# PRU_ICSS_MII_RT register map
Vendor: Texas Instruments
Peripheral module from a debugger description file (folder am437x).
Registers are 32-bit, read-only, no defined reset value unless marked. A register's access mark holds for its fields unless they carry their own. Offsets are as the file gives them; lines under a group give offsets from that group; [hi:lo] are bit positions; {n}, {i} and the like mark numbered series; 'fields as' and 'values as' point back to an identical list; <NAME> marks a mode.

## PRU_ICSS_MII_RT
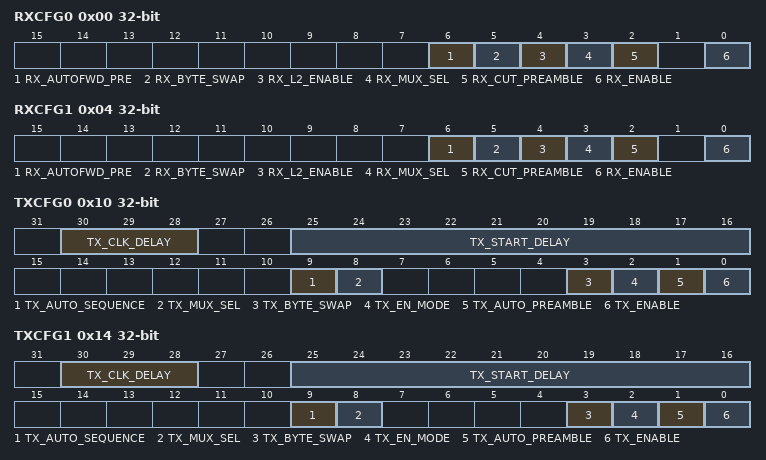
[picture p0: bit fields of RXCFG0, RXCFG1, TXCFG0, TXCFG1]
0x00 RXCFG0 access per field — RX CONFIG0
  [6] RX_AUTOFWD_PRE rw — Enables auto-forward of received preamble. When enabled, this will forward the preamble nibbles including the SFD to the TX L1 FIFO that is attached to the PRU. First data byte seen by PRU R31 and/or RX L2 is destination address (DA). Odd number of preamble nibbles is supported in this mode. For example, 0x55D. Note that new RX should only occur after the current TX completes. 0x0: Disable 0x1: Enable, it must disable RX_CUT_PREAMBLE and TX_AUTO_PREAMBLE
  [5] RX_BYTE_SWAP rw — Defines the order of Byte0/1 placement for RX R31 and RX L2. Note that if TX_AUTO_SEQUENCE enabled, this bit cannot get enable since TX_BYTE_SWAP on swaps the PRU output. This bit must be selected/updated when the port is disabled or there is no traffic. 0x0: R31[15:8]/RXL2[15:8] = Byte1{Nibble3,Nibble2} R31[ 7:0]/RXL2[7:0] = Byte0{Nibble1,Nibble0} 0x1: R31[15:8]/RXL2[15:8] = Byte0{Nibble1,Nibble0} R31[ 7:0]/RXL2[7:0] = Byte1{Nibble3,Nibble2} Nibble0 is the first nibble received.
  [4] RX_L2_ENABLE rw — Enables RX L2 buffer. 0x0: Disable (RX L2 can function as generic scratch pad) 0x1: Enable
  [3] RX_MUX_SEL rw — Selects receive data source. Typically, the setting for this will not be identical for the two MII receive configuration registers. 0x0: MII RX Data from Port 0 (default for RXCFG0) 0x1: MII RX Data from Port 1 (default for RXCFG1)
  [2] RX_CUT_PREAMBLE rw — Removes received preamble. 0x0: All data from Ethernet PHY are passed on to PRU register. This assumes Ethernet PHY which does not shorten the preamble. 0x1: MII interface suppresses preamble and sync frame delimiter. First data byte seen by PRU register is destination address.
  [0] RX_ENABLE rw — Enables the receive traffic currently selected by RX_MUX_SELECT. 0x0: Disable 0x1: Enable
0x04 RXCFG1 access per field — RX CONFIG1
  fields as RXCFG0
0x10 TXCFG0 access per field — TX CONFIG0
  [30:28] TX_CLK_DELAY rw — In order to guarantee the MII_RT IO timing values published in the device data manual, the ocp_clk must be configured for 200MHz and TX_CLK_DELAY must be set to 6h.
  [25:16] TX_START_DELAY rw — Defines the minimum time interval (delay) between receiving the RXDV for the current frame and the start of the transmit interface sending data to the MII interface. Delay value is in units of MII_RT clock cycles, which uses the ocp_clk (default is 200MHz, or 5ns). Default TX_START_DELAY value is 320ns, which is optimized for minimum latency at 16 bit processing. Counter is started with RX_DV signal going active. Transmit interface stops sending data when no more data is written into transmit interface by PRU along with TX_EOF marker bit set. If the TX FIFO has data when the delay expires, then TX will start sending data. But if the TX FIFO is empty, it will not start until the TX FIFO is not empty. It is possible to overflow the TX FIFO with the max delay setting when auto-forwarding is enabled since the time delay is larger than the amount of data it needs to store. As long as TX L1 FIFO overflows, software will need to issue a TX_RESET to reset the TX FIFO. The total delay is 64-byte times (size of TX FIFO), but you need to allow delays for synchronization. Do to this fact, the maximum delay should be 80ns less when auto forwarding is enabled. Therefore, 0x3F0 is the maximum in this configuration.
  [9] TX_AUTO_SEQUENCE rw — Enables transmit auto-sequence. Note the transmit data source is determined by TX_MUX_SEL setting. 0x0: Disable 0x1: Enable, transmit state machine based on events on receiver path that is connected to the respective transmitter. Also, the masking logic is disabled and only the MII data is used.
  [8] TX_MUX_SEL rw — Selects transmit data source. The default/reset setting for TX Port 0 is 1. This setting permits MII TX Port 0 to receive data from PRU1 and the MII TX Port 1 which is connected to PRU0 by default. 0x0: Data from PRU0 (default for TXCFG1) 0x1: Data from PRU1 (default for TXCFG0)
  [3] TX_BYTE_SWAP rw — Defines the order of Byte0/1 placement for TX R30. This bit must be selected/updated when the port is disabled or there is no traffic. 0x0: R30[15:8] = Byte1{Nibble3,Nibble2} R30[ 7:0] = Byte0{Nibble1,Nibble0} R30[31:24] = TX_MASK[15:8] R30[23:16] = TX_MASK[7:0] 0x1: R30[15:8] = Byte0{Nibble1,Nibble0} R30[ 7:0] = Byte1{Nibble3,Nibble2} R30[31:24] = TX_MASK[7:0] R30[23:16] = TX_MASK[15:8] Nibble0 is the first nibble received.
  [2] TX_EN_MODE rw — Enables transmit self clear on TX_EOF event. Note that iep.cmp[3] must be set before transmission will start for TX0, and iep_cmp[4] for TX1. This is a new dependency, in addition to TX L1 FIFO not empty and TX_START_DELAY expiration, to start transmission. 0x0: Disable 0x1: Enable, TX_ENABLE will be clear for a TX_EOF event by itself.
  [1] TX_AUTO_PREAMBLE rw — Transmit data auto-preamble. 0x0: PRU will provide full preamble 0x1: TX FIFO will insert pre-amble automatically. Note that the TX FIFO does not get preloaded with the preamble until the first write occurs. This can cause the latency to be larger than the minimum latency.
  [0] TX_ENABLE rw — Enables transmit traffic on TX PORT. If TX_EN_MODE is set, then TX_ENABLE will self clear during a TX_EOF event. Note Software can use this to pre-fill the TX FIFO and then start the TX frame during non-ECS operations. 0x0: TX PORT is disabled/stopped immediately 0x1: TX PORT is enabled and the frame will start once the IPG counter expired and TX Start Delay counter has expired
0x14 TXCFG1 access per field — TX CONFIG1
  fields as TXCFG0
0x20 TXCRC0 — TX CYCLIC REDUNDANCY CHECK0
  [31:0] TX_CRC32 — FCS (CRC32) data can be read by PRU for diagnostics. It is only valid after 6 clocks after a TX_CRC_HIGH command is given.
0x24 TXCRC1 — TX CYCLIC REDUNDANCY CHECK1
  fields as TXCRC0
0x30 TXIPG0 access per field — TX INTERPACKET GAP0
  [9:0] TX_IPG rw — Defines the minimum of transmit Inter Packet Gap (IPG) which is the number of ocp_clk cycles between the de-assertion of TX_EN and the assertion of TX_EN. The start of the TX will get delayed when the incoming packet IPG is less than defined minimum value. In general, software should program in increments of 8, 40ns to insure the extra delays takes effect.
0x34 TXIPG1 access per field — TX INTERPACKET GAP1
  fields as TXIPG0
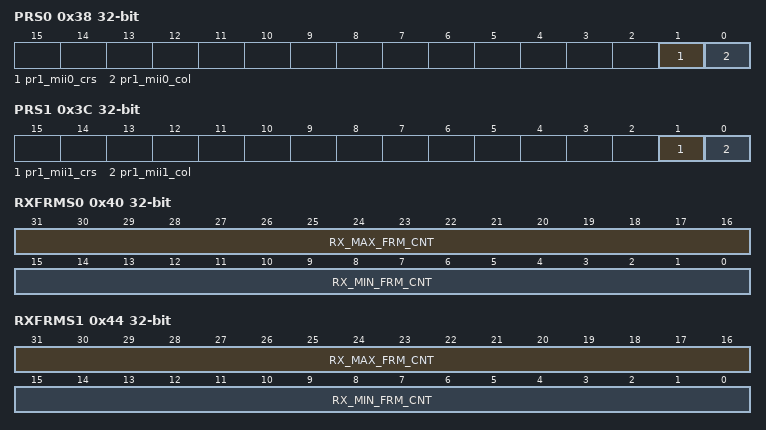
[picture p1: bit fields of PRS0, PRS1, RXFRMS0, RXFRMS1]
0x38 PRS0 — PORT RAW STATUS0
  [1] pr1_mii0_crs — Current state of pr#lt#k#gt#_mii0_crs
  [0] pr1_mii0_col — Current state of pr#lt#k#gt#_mii0_col
0x3C PRS1 — PORT RAW STATUS1
  [1] pr1_mii1_crs — Current state of pr#lt#k#gt#_mii1_crs
  [0] pr1_mii1_col — Current state of pr#lt#k#gt#_mii1_col
0x40 RXFRMS0 rw — RX FRAME SIZE0
  [31:16] RX_MAX_FRM_CNT — Defines the maximum received frame count. If the total byte count of the received frame is more than defined value, RX_MAX_FRM_ERR will get set. 0x0: 1 byte after SFD and including CRC. N: N+1 bytes after SFD and including CRC Note if the incoming frame is truncated at the marker, RX_CRC and RX_NIBBLE_ODD will not get asserted.
  [15:0] RX_MIN_FRM_CNT — Defines the minimum received frame count. If the total byte count of received frame is less than defined value, RX_MIN_FRM_ERR will get set. 0x0: 1 byte after SFD and including CRC. N: N+1 bytes after SFD and including CRC
0x44 RXFRMS1 rw — RX FRAME SIZE1
  fields as RXFRMS0
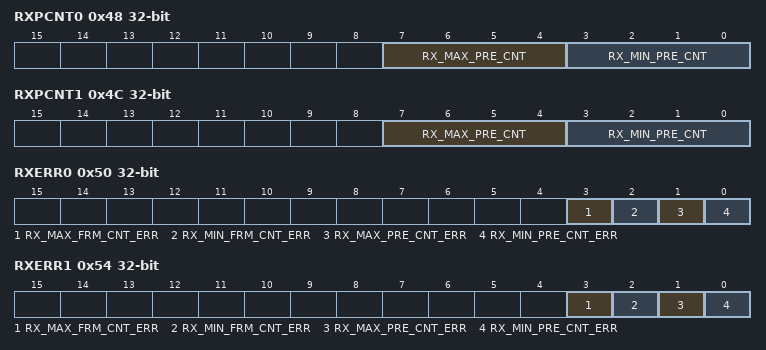
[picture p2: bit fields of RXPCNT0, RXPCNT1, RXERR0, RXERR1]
0x48 RXPCNT0 access per field — RX PREAMABLE COUNT0
  [7:4] RX_MAX_PRE_CNT rw — Defines the maximum number of nibbles until the start of frame delimiter (SFD) event occurred (i.e. matches 0x5D). RX_MAX_PRE_COUNT_ERR will be set if the preamble counts more than the value of RX_MAX_PRE_CNT. If the SFD does not occur within 16 nibbles, the error will assert and the incoming frame will be truncated. 0x0: Disabled 0x1: Reserved 0x2: 4th nibble needs to have built 0x5D 0xe: 16th nibble needs to have built 0x5D Note the 16th nibble is transmitted.
  [3:0] RX_MIN_PRE_CNT rw — Defines the minimum number of nibbles until the start of frame delimiter (SFD) event occurred, which is matched the value 0x5D. RX_MIN_PRE_COUNT_ERR will be set if the preamble counts less than the value of RX_MIN_PRE_CNT. 0x0: Disabled 0x1: 1 0x5 before 0x5D 0x2: 2 0x5 before 0x5D N: N 0x5 before 0x5D Note it does not need to be 0x5.
0x4C RXPCNT1 access per field — RX PREAMABLE COUNT1
  fields as RXPCNT0
0x50 RXERR0 — RX ERROR0
  [3] RX_MAX_FRM_CNT_ERR — Error status of received frame is more than the value of RX_MAX_FRM_CNT. 0x0: No error occurred 0x1: Error occurred
  [2] RX_MIN_FRM_CNT_ERR — Error status of received frame is less than the value of RX_MIN_FRM_CNT. 0x0: No error occurred 0x1: Error occurred
  [1] RX_MAX_PRE_CNT_ERR — Error status of received preamble nibble is more than the value of RX_MAX_PRE_CNT. 0x0: No error occurred 0x1: Error occurred
  [0] RX_MIN_PRE_CNT_ERR — Error status of received preamble nibble is less than the value of RX_MIN_PRE_CNT. 0x0: No error occurred 0x1: Error occurred
0x54 RXERR1 — RX ERROR1
  fields as RXERR0
0x60 RXFLV0 — RX FIFO0 Level
  [7:0] RX_FIFO_LEVEL — Define the number of valid bytes in the RX FIFO 0 = empty 1 = 1 Byte/ 2 Nibbles 2 = 2 Byte/ 4 Nibble ... 32 = 32 Bytes/ 64 Nibbles
0x64 RXFLV1 — RX FIFO1 Level
  fields as RXFLV0
0x68 TXFLV0 — TX FIFO0 Level
  [7:0] TX_FIFO_LEVEL — Define the number of valid nibbles in the TX FIFO 0 = empty 1 = 1 Nibble 2 = 1 Byte/ 2 Nibble ... 128 = 64 Bytes/ 128 Nibbles
0x6C TXFLV1 — TX FIFO1 Level
  fields as TXFLV0
